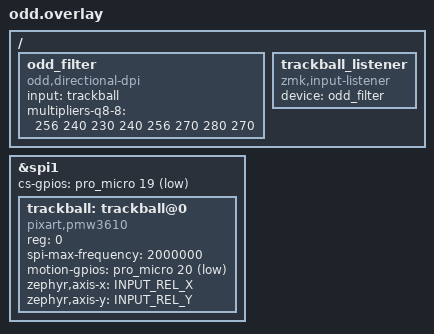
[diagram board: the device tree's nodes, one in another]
/*
 * ZMK compile check (CI): PMW3610 sensor -> odd,directional-dpi -> zmk,input-listener.
 * west build -s app -b nice_nano//zmk -- -DSHIELD=romac -DZMK_EXTRA_MODULES=<repo>
 *   -DEXTRA_DTC_OVERLAY_FILE=<this file> -DEXTRA_CONF_FILE=<odd.conf next to it>
 */
#include <zephyr/dt-bindings/input/input-event-codes.h>

&spi1 {
    status = "okay";
    cs-gpios = <&pro_micro 19 GPIO_ACTIVE_LOW>;

    trackball: trackball@0 {
        compatible = "pixart,pmw3610";
        reg = <0>;
        spi-max-frequency = <2000000>;
        motion-gpios = <&pro_micro 20 (GPIO_ACTIVE_LOW | GPIO_PULL_UP)>;
        zephyr,axis-x = <INPUT_REL_X>;
        zephyr,axis-y = <INPUT_REL_Y>;
    };
};

/ {
    odd_filter: odd_filter {
        compatible = "odd,directional-dpi";
        input = <&trackball>;
        multipliers-q8-8 = <256 240 230 240 256 270 280 270>;
    };

    trackball_listener {
        compatible = "zmk,input-listener";
        device = <&odd_filter>;
    };
};
